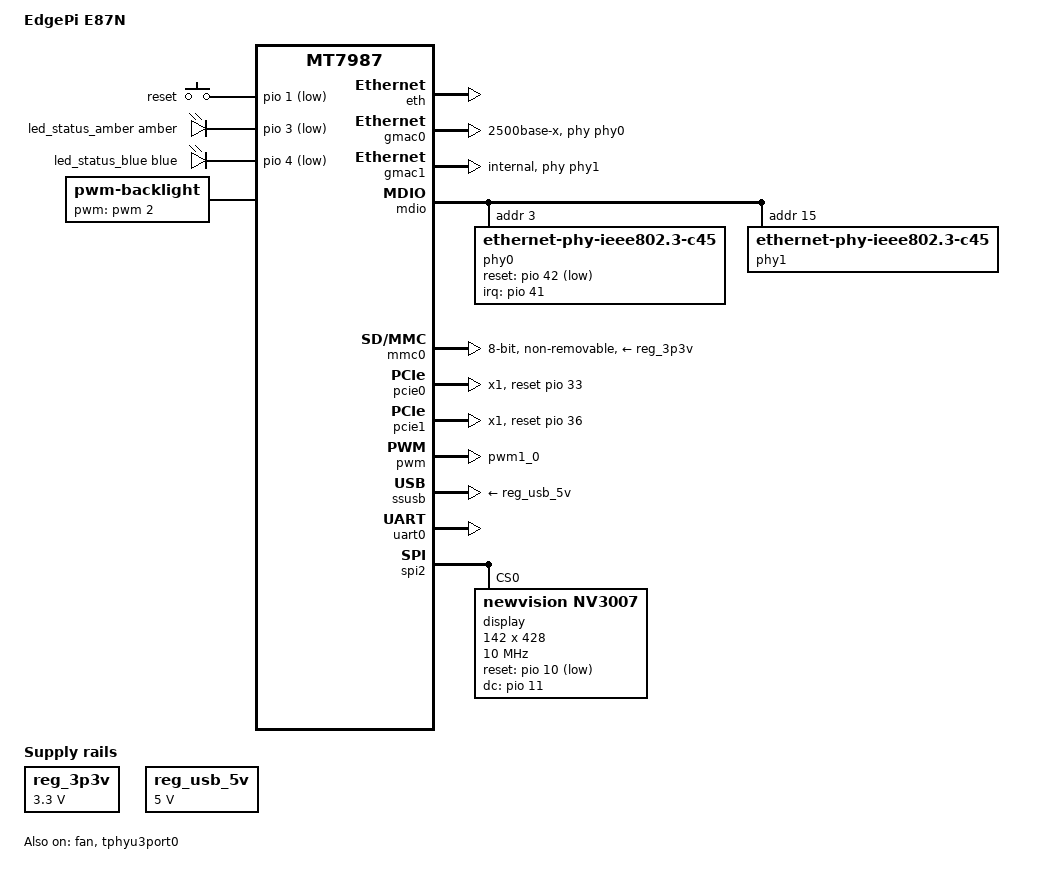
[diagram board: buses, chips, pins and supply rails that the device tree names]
// SPDX-License-Identifier: (GPL-2.0 OR MIT)

/dts-v1/;
#include "mt7987a.dtsi"
#include <dt-bindings/input/input.h>

/ {
	model = "EdgePi E87N";
	compatible = "edgepi,e87n", "mediatek,mt7987a", "mediatek,mt7987";

	aliases {
		led-boot = &led_status_blue;
		led-failsafe = &led_status_amber;
		led-upgrade = &led_status_amber;
		serial0 = &uart0;
	};

	chosen {
		bootargs = "earlycon=uart8250,mmio32,0x11000000 \
			    root=PARTLABEL=rootfs rootwait pci=pcie_bus_perf";
		stdout-path = "serial0:115200n8";
	};

	gpio-keys {
		compatible = "gpio-keys";

		button-reset {
			label = "reset";
			linux,code = <KEY_RESTART>;
			gpios = <&pio 1 GPIO_ACTIVE_LOW>;
			debounce-interval = <10>;
		};
	};

	/*
	 * LED Indicator Layout
	 * -------------------
	 * Two general-purpose, software-controllable status LEDs.
	 * The board has no WiFi radio, so these are not WLAN indicators.
	 */
	leds {
		compatible = "gpio-leds";

		led_status_amber: led-1 {
			function = LED_FUNCTION_STATUS;
			color = <LED_COLOR_ID_AMBER>;
			gpios = <&pio 3 GPIO_ACTIVE_LOW>;
		};

		led_status_blue: led-2 {
			function = LED_FUNCTION_INDICATOR;
			color = <LED_COLOR_ID_BLUE>;
			gpios = <&pio 4 GPIO_ACTIVE_LOW>;
		};
	};

	reg_3p3v: regulator-3p3v {
		compatible = "regulator-fixed";
		regulator-name = "fixed-3.3V";
		regulator-min-microvolt = <3300000>;
		regulator-max-microvolt = <3300000>;
		regulator-boot-on;
		regulator-always-on;
	};

	reg_usb_5v: regulator-usb-5v {
		compatible = "regulator-fixed";
		regulator-name = "usb-5v";
		regulator-max-microvolt = <5000000>;
		regulator-min-microvolt = <5000000>;
		regulator-boot-on;
		regulator-always-on;
	};
	backlight: backlight {
		compatible = "pwm-backlight";
		pinctrl-names = "default";
		pinctrl-0 = <&pwm_backlight_pins>;
		pwms = <&pwm 2 50000>;
		brightness-levels = <0 10 20 30 40 50 60 70 80 90 100 110 120
			130 140 150 160 170 180 190 200 210 220 230 240 250 255>;
		default-brightness-level = <16>;
		status = "okay";
	};
};

&eth {
	status = "okay";
};

&fan {
	pwms = <&pwm 1 50000 0>;
	status = "okay";
};

&gmac0 {
	phy-mode = "2500base-x";
	phy-handle = <&phy0>;
	status = "okay";
};

&gmac1 {
	phy-mode = "internal";
	phy-handle = <&phy1>;
	status = "okay";
};

&mdio {
	/* RTL8221B-VB-CG 2.5Gbps PHY (away from power) eth0 */
	phy0: phy@3 {
		compatible = "ethernet-phy-ieee802.3-c45";
		reg = <3>;
		reset-gpios = <&pio 42 GPIO_ACTIVE_LOW>;
		reset-assert-us = <100000>;
		reset-deassert-us = <100000>;
		interrupt-parent = <&pio>;
		interrupts = <41 IRQ_TYPE_LEVEL_LOW>;
		realtek,aldps-enable;
	};

	/* built-in 2.5G Ethernet PHY (near power) eth1 */
	phy1: phy@15 {
		compatible = "ethernet-phy-ieee802.3-c45";
		reg = <15>;
		pinctrl-names = "i2p5gbe-led";
		pinctrl-0 = <&i2p5gbe_led0_pins>;

		leds {
			#address-cells = <1>;
			#size-cells = <0>;

			led@0 {
				reg = <0>;
				function = LED_FUNCTION_WAN;
				color = <LED_COLOR_ID_RED>;
			};
		};
	};
};

&mmc0 {
	pinctrl-names = "default", "state_uhs";
	pinctrl-0 = <&mmc_pins_default>;
	pinctrl-1 = <&mmc_pins_uhs>;
	bus-width = <8>;
	max-frequency = <48000000>;
	cap-mmc-highspeed;
	vmmc-supply = <&reg_3p3v>;
	non-removable;
	status = "okay";
};

&pcie0 {
	pinctrl-names = "default";
	pinctrl-0 = <&pcie0_pins>;
	reset-gpios = <&pio 33 GPIO_ACTIVE_HIGH>;
	num-lanes = <1>;
	status = "okay";
};

&pcie1 {
	pinctrl-names = "default";
	pinctrl-0 = <&pcie1_pins>;
	reset-gpios = <&pio 36 GPIO_ACTIVE_HIGH>;
	num-lanes = <1>;
	status = "okay";
};

&pio {
	pwm_fan_pins: pwm-fan-pins {
		mux {
			function = "pwm";
			groups = "pwm1_0";
		};
	};

	pwm_backlight_pins: pwm-backlight-pins {
		mux {
			function = "pwm";
			groups = "pwm2_0";
		};
	};
};

&pwm {
	status = "okay";
	pinctrl-names = "default";
	pinctrl-0 = <&pwm_fan_pins>;
};

&ssusb {
	status = "okay";
	vusb33-supply = <&reg_3p3v>;
	vbus-supply = <&reg_usb_5v>;
};

&tphyu3port0 {
	status = "okay";
};

&uart0 {
	pinctrl-names = "default";
	pinctrl-0 = <&uart0_pins>;
	status = "okay";
};

/* Values transcribed from the vendor E87N FIT device tree. */
&spi2 {
	pinctrl-names = "default";
	pinctrl-0 = <&spi2_flash_pins>;
	status = "okay";

	display@0 {
		compatible = "newvision,nv3007";
		reg = <0>;
		regwidth = <8>;
		buswidth = <8>;
		height = <428>;
		width = <142>;
		fps = <100>;
		rotate = <270>;
		reset-gpios = <&pio 10 GPIO_ACTIVE_LOW>;
		dc-gpios = <&pio 11 GPIO_ACTIVE_HIGH>;
		spi-max-frequency = <10000000>;
		status = "okay";
	};
};
